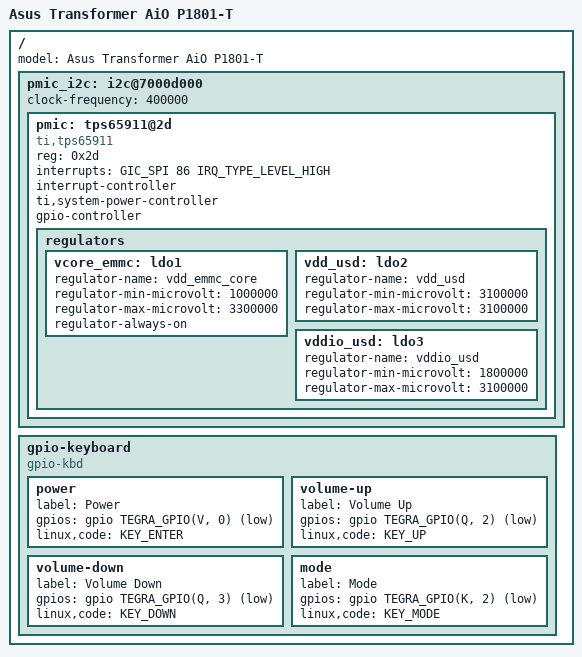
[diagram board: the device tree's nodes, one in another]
// SPDX-License-Identifier: GPL-2.0-or-later
/dts-v1/;

#include <dt-bindings/input/gpio-keys.h>
#include <dt-bindings/input/linux-event-codes.h>

#include "tegra30-asus-transformer.dtsi"

/ {
	model = "Asus Transformer AiO P1801-T";

	pmic_i2c: i2c@7000d000 {
		status = "okay";
		clock-frequency = <400000>;

		/* Texas Instruments TPS659110 PMIC */
		pmic: tps65911@2d {
			compatible = "ti,tps65911";
			reg = <0x2d>;

			interrupts = <GIC_SPI 86 IRQ_TYPE_LEVEL_HIGH>;
			#interrupt-cells = <2>;
			interrupt-controller;

			ti,system-power-controller;

			#gpio-cells = <2>;
			gpio-controller;

			regulators {
				/* eMMC VDD */
				vcore_emmc: ldo1 {
					regulator-name = "vdd_emmc_core";
					regulator-min-microvolt = <1000000>;
					regulator-max-microvolt = <3300000>;
					regulator-always-on;
				};

				/* uSD slot VDD */
				vdd_usd: ldo2 {
					regulator-name = "vdd_usd";
					regulator-min-microvolt = <3100000>;
					regulator-max-microvolt = <3100000>;
				};

				/* uSD slot VDDIO */
				vddio_usd: ldo3 {
					regulator-name = "vddio_usd";
					regulator-min-microvolt = <1800000>;
					regulator-max-microvolt = <3100000>;
				};
			};
		};
	};

	gpio-keyboard {
		compatible = "gpio-kbd";

		power {
			label = "Power";
			gpios = <&gpio TEGRA_GPIO(V, 0) GPIO_ACTIVE_LOW>;
			linux,code = <KEY_ENTER>;
		};

		volume-up {
			label = "Volume Up";
			gpios = <&gpio TEGRA_GPIO(Q, 2) GPIO_ACTIVE_LOW>;
			linux,code = <KEY_UP>;
		};

		volume-down {
			label = "Volume Down";
			gpios = <&gpio TEGRA_GPIO(Q, 3) GPIO_ACTIVE_LOW>;
			linux,code = <KEY_DOWN>;
		};

		mode {
			label = "Mode";
			gpios = <&gpio TEGRA_GPIO(K, 2) GPIO_ACTIVE_LOW>;
			linux,code = <KEY_MODE>;
		};
	};
};
